# PIC32CM5164LE00048 register map
Vendor: Microchip Technology; Series: PIC32CMLE00; File version: 0
CPU: CM23 r0p0, little endian, MPU, no FPU, 2 interrupt priority bits, 71 interrupts
Registers are 32-bit, read-write, reset 0x0 unless marked. A register's access mark holds for its fields unless they carry their own. Offsets are from the block's base; [hi:lo] are bit positions; lines under a group give offsets from that group; {n}, {i} and the like mark numbered series; 'fields as' and 'values as' point back to an identical list.

## SERCOM0 — Serial Communication Interface
Base 0x42000400; register names take the prefix SERCOM_
Same registers: SERCOM1 0x42000800, SERCOM2 0x42000C00, SERCOM3 0x42001000, SERCOM4 0x42001400, SERCOM5 0x42001800
0x00 I2CM group — I2C Master Mode
  0x00 CTRLA — I2CM Control A
    [30] LOWTOUTEN — SCL Low Timeout Enable
    [29:28] INACTOUT — Inactive Time-Out
      0=DIS (Disable); 1=55US (5-6 SCL cycle time-out); 2=105US (10-11 SCL cycle time-out); 3=205US (20-21 SCL cycle time-out)
    [27] SCLSM — SCL Clock Stretch Mode
    [25:24] SPEED — Transfer Speed
      0=SM (Standard-Mode (SM) and Fast-Mode (FM)); 1=FMP (Fast-Mode Plus (FM+)); 2=HS (High-Speed Mode)
    [23] SEXTTOEN — Slave SCL Low Extend Timeout
    [22] MEXTTOEN — Master SCL Low Extend Timeout
    [21:20] SDAHOLD — SDA Hold Time
      0=DIS (Disabled); 1=75NS (50-100ns hold time); 2=450NS (300-600ns hold time); 3=600NS (400-800ns hold time)
    [16] PINOUT — Pin Usage
    [7] RUNSTDBY — Run in Standby
    [4:2] MODE — Operating Mode
      5=I2C_MASTER (I2C master operation)
    [1] ENABLE
    [0] SWRST — Software Reset
  0x04 CTRLB — I2CM Control B
    [23:22] FIFOCLR — FIFO Clear
      0=NONE (No action); 1=TXFIFO (Clear TX FIFO); 2=RXFIFO (Clear RX FIFO); 3=BOTH (Clear both TX and RF FIFOs)
    [18] ACKACT — Acknowledge Action
    [17:16] CMD — Command
    [9] QCEN — Quick Command Enable
    [8] SMEN — Smart Mode Enable
  0x08 CTRLC — I2CM Control C
    [31:30] TXTRHOLD — Transmit FIFO Threshold
      0=DEFAULT (Interrupt and DMA triggers are generated as long as the FIFO is not full); 1=HALF (Interrupt and DMA triggers are generated when half FIFO space is free); 2=EMPTY (Interrupt and DMA triggers are generated as long as the FIFO is not full)
    [29:28] RXTRHOLD — Receive FIFO Threshold
      0=DEFAULT (Interrupt and DMA triggers are generated when DATA is present in the FIFO); 1=HALF (Interrupt and DMA triggers are generated when FIFO is half-full); 2=FULL (Interrupt and DMA triggers are generated when FIFO is full)
    [27] FIFOEN — FIFO Enable
    [24] DATA32B — Data 32 Bit
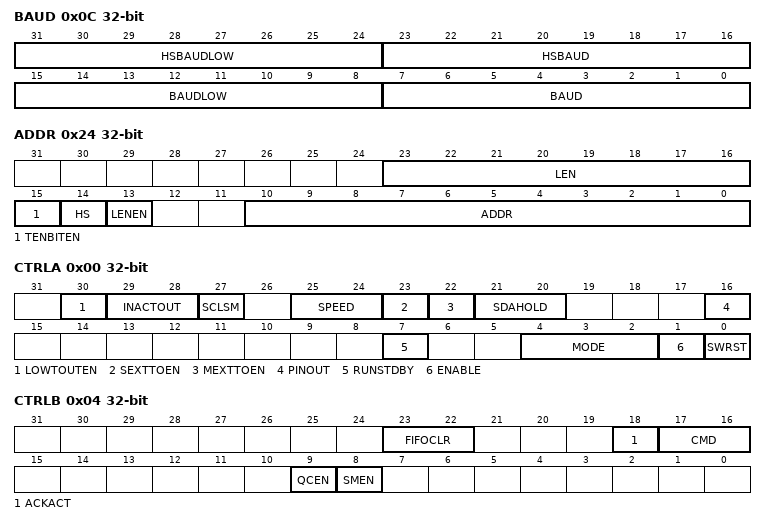
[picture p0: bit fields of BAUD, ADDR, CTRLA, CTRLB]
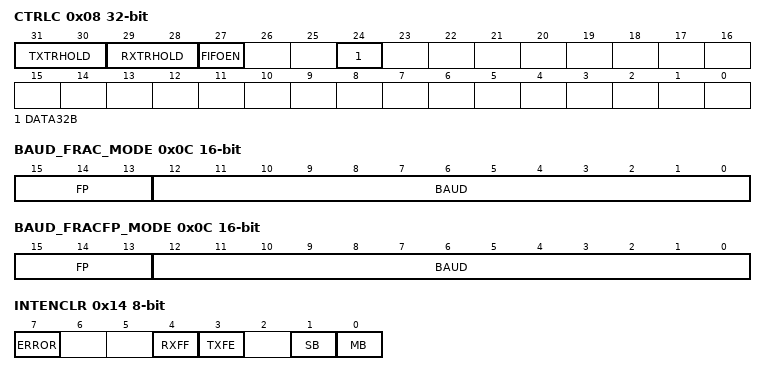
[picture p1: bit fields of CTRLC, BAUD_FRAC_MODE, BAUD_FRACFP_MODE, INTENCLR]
  0x0C BAUD — I2CM Baud Rate
    [31:24] HSBAUDLOW — High Speed Baud Rate Value Low
    [23:16] HSBAUD — High Speed Baud Rate Value
    [15:8] BAUDLOW — Baud Rate Value Low
    [7:0] BAUD — Baud Rate Value
  0x14 INTENCLR 8-bit write-1-clears — I2CM Interrupt Enable Clear
    [7] ERROR — Combined Error Interrupt Disable
    [4] RXFF — Rx FIFO Full Interrupt Disable
    [3] TXFE — Tx FIFO Empty Interrupt Disable
    [1] SB — Slave On Bus Interrupt Disable
    [0] MB — Master On Bus Interrupt Disable
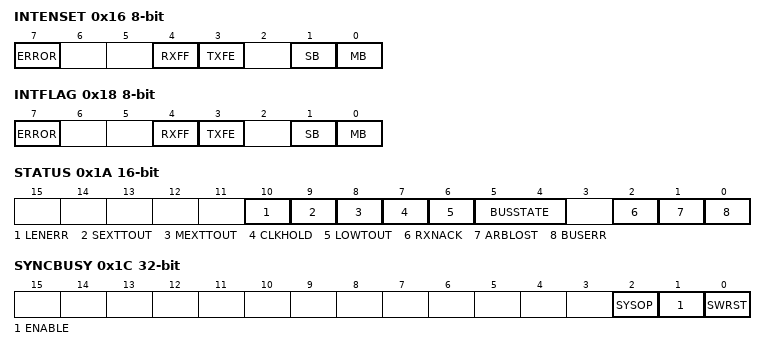
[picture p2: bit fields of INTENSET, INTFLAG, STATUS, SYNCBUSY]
  0x16 INTENSET 8-bit write-1-sets — I2CM Interrupt Enable Set
    [7] ERROR — Combined Error Interrupt Enable
    [4] RXFF — Rx FIFO Full Interrupt Enable
    [3] TXFE — Tx FIFO Empty Interrupt Enable
    [1] SB — Slave On Bus Interrupt Enable
    [0] MB — Master On Bus Interrupt Enable
  0x18 INTFLAG 8-bit write-1-clears — I2CM Interrupt Flag Status and Clear
    [7] ERROR — Combined Error Interrupt
    [4] RXFF — Rx FIFO Full Interrupt
    [3] TXFE — Tx FIFO Empty Interrupt
    [1] SB — Slave On Bus Interrupt
    [0] MB — Master On Bus Interrupt
  0x1A STATUS 16-bit — I2CM Status
    [10] LENERR — Length Error
    [9] SEXTTOUT — Slave SCL Low Extend Timeout
    [8] MEXTTOUT — Master SCL Low Extend Timeout
    [7] CLKHOLD — Clock Hold
    [6] LOWTOUT — SCL Low Timeout
    [5:4] BUSSTATE
      0=UNKNOWN (Wait for stop or idle); 1=IDLE (Wait for transaction initialization); 2=OWNER (I2C master is the current owner of the bus); 3=BUSY (Some other I2C master owns the bus)
    [2] RXNACK — Received Not Acknowledge
    [1] ARBLOST — Arbitration Lost
    [0] BUSERR — Bus Error
  0x1C SYNCBUSY ro — I2CM Synchronization Busy
    [2] SYSOP — System Operation Synchronization Busy
    [1] ENABLE — SERCOM Enable Synchronization Busy
    [0] SWRST — Software Reset Synchronization Busy
  0x24 ADDR — I2CM Address
    [23:16] LEN — Length
    [15] TENBITEN — Ten Bit Addressing Enable
    [14] HS — High Speed Mode
    [13] LENEN — Length Enable
    [10:0] ADDR — Address Value
  0x28 DATA — I2CM Data
    [31:0] DATA — Data Value
  0x30 DBGCTRL 8-bit — I2CM Debug Control
    [0] DBGSTOP — Debug Mode
  0x34 FIFOSPACE 16-bit ro — I2CM FIFO Space
    [12:8] RXSPACE — Rx FIFO Filled Space
    [4:0] TXSPACE — Tx FIFO Empty Space
  0x36 FIFOPTR 16-bit — I2CM FIFO CPU Pointers
    [11:8] CPURDPTR — CPU FIFO Read Pointer
    [3:0] CPUWRPTR — CPU FIFO Write Pointer
0x00 I2CS group (alternate view of I2CM) — I2C Slave Mode
  0x00 CTRLA — I2CS Control A
    [30] LOWTOUTEN — SCL Low Timeout Enable
    [27] SCLSM — SCL Clock Stretch Mode
    [25:24] SPEED — Transfer Speed
      values as I2CM.CTRLA.SPEED
    [23] SEXTTOEN — Slave SCL Low Extend Timeout
    [21:20] SDAHOLD — SDA Hold Time
      values as I2CM.CTRLA.SDAHOLD
    [16] PINOUT — Pin Usage
    [7] RUNSTDBY — Run during Standby
    [4:2] MODE — Operating Mode
      4=I2C_SLAVE (I2C slave operation)
    [1] ENABLE
    [0] SWRST — Software Reset
  0x04 CTRLB — I2CS Control B
    [23:22] FIFOCLR — FIFO Clear
      values as I2CM.CTRLB.FIFOCLR
    [18] ACKACT — Acknowledge Action
    [17:16] CMD — Command
    [15:14] AMODE — Address Mode
      0=MASK (The slave responds to the address written in ADDR.ADDR masked by the value in ADDR.ADDRMASK); 1=2ADDRS (The slave responds to the two unique addresses in ADDR and ADDRMASK); 2=RANGE (The slave responds to the range of addresses between and including ADDR and ADDRMASK. ADDR is the upper limit)
    [10] AACKEN — Automatic Address Acknowledge
    [9] GCMD — PMBus Group Command
    [8] SMEN — Smart Mode Enable
  0x08 CTRLC — I2CS Control C
    [31:30] TXTRHOLD — Transmit FIFO Threshold
      values as I2CM.CTRLC.TXTRHOLD
    [29:28] RXTRHOLD — Receive FIFO Threshold
      values as I2CM.CTRLC.RXTRHOLD
    [27] FIFOEN — FIFO Enable
    [24] DATA32B — Data 32 Bit
    [3:0] SDASETUP — SDA Setup Time
  0x14 INTENCLR 8-bit write-1-clears — I2CS Interrupt Enable Clear
    [7] ERROR — Combined Error Interrupt Disable
    [4] RXFF — Rx FIFO Full Interrupt Disable
    [3] TXFE — Tx FIFO Empty Interrupt Disable
    [2] DRDY — Data Interrupt Disable
    [1] AMATCH — Address Match Interrupt Disable
    [0] PREC — Stop Received Interrupt Disable
  0x16 INTENSET 8-bit write-1-sets — I2CS Interrupt Enable Set
    [7] ERROR — Combined Error Interrupt Enable
    [4] RXFF — Rx FIFO Full Interrupt Enable
    [3] TXFE — Tx FIFO Empty Interrupt Enable
    [2] DRDY — Data Interrupt Enable
    [1] AMATCH — Address Match Interrupt Enable
    [0] PREC — Stop Received Interrupt Enable
  0x18 INTFLAG 8-bit write-1-clears — I2CS Interrupt Flag Status and Clear
    [7] ERROR — Combined Error Interrupt
    [4] RXFF — Rx FIFO Full Interrupt
    [3] TXFE — Tx FIFO Empty Interrupt
    [2] DRDY — Data Interrupt
    [1] AMATCH — Address Match Interrupt
    [0] PREC — Stop Received Interrupt
  0x1A STATUS 16-bit — I2CS Status
    [11] LENERR — Transaction Length Error
    [10] HS — High Speed
    [9] SEXTTOUT — Slave SCL Low Extend Timeout
    [7] CLKHOLD — Clock Hold
    [6] LOWTOUT — SCL Low Timeout
    [4] SR — Repeated Start
    [3] DIR — Read/Write Direction
    [2] RXNACK — Received Not Acknowledge
    [1] COLL — Transmit Collision
    [0] BUSERR — Bus Error
  0x1C SYNCBUSY ro — I2CS Synchronization Busy
    [4] LENGTH — Length Synchronization Busy
    [2] SYSOP — System Operation Synchronization Busy
    [1] ENABLE — SERCOM Enable Synchronization Busy
    [0] SWRST — Software Reset Synchronization Busy
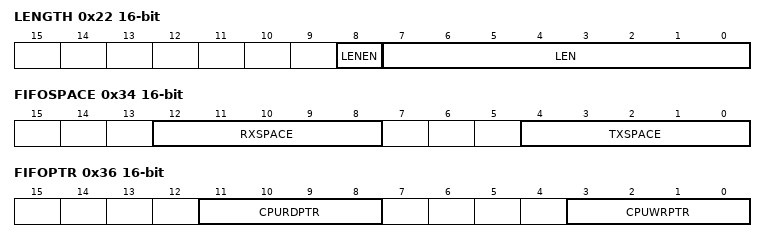
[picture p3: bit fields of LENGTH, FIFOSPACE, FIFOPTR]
  0x22 LENGTH 16-bit — I2CS Length
    [8] LENEN — Data Length Enable
    [7:0] LEN — Data Length
  0x24 ADDR — I2CS Address
    [26:17] ADDRMASK — Address Mask
    [15] TENBITEN — Ten Bit Addressing Enable
    [10:1] ADDR — Address Value
    [0] GENCEN — General Call Address Enable
  0x28 DATA — I2CS Data
    [31:0] DATA — Data Value
  0x34 FIFOSPACE 16-bit ro — I2CS FIFO Space
    fields as I2CM.FIFOSPACE
  0x36 FIFOPTR 16-bit — I2CS FIFO CPU Pointers
    fields as I2CM.FIFOPTR
0x00 SPIS group (alternate view of I2CM) — SPI Slave Mode
  0x00 CTRLA — SPIS Control A
    [30] DORD — Data Order
      0=MSB (MSB is transmitted first); 1=LSB (LSB is transmitted first)
    [29] CPOL — Clock Polarity
      0=IDLE_LOW (SCK is low when idle); 1=IDLE_HIGH (SCK is high when idle)
    [28] CPHA — Clock Phase
      0=LEADING_EDGE (The data is sampled on a leading SCK edge and changed on a trailing SCK edge); 1=TRAILING_EDGE (The data is sampled on a trailing SCK edge and changed on a leading SCK edge)
    [27:24] FORM — Frame Format
      0=SPI_FRAME; 2=SPI_FRAME_WITH_ADDR
    [21:20] DIPO — Data In Pinout
      {v}=PAD{v} (SERCOM PAD[{v}] is used as data input) (v=0..3)
    [17:16] DOPO — Data Out Pinout
      0=PAD0 (DO on PAD[0], SCK on PAD[1] and SS on PAD[2]); 2=PAD3 (DO on PAD[3], SCK on PAD[1] and SS on PAD[2])
    [8] IBON — Immediate Buffer Overflow Notification
      0=STATUS.BUFOVF is set when it occurs in the data stream; 1=STATUS.BUFOVF is set immediately upon buffer overflow
    [7] RUNSTDBY — Run during Standby
    [4:2] MODE — Operating Mode
      2=SPI_SLAVE (SPI in slave operation)
    [1] ENABLE
    [0] SWRST — Software Reset
  0x04 CTRLB — SPIS Control B
    [23:22] FIFOCLR — FIFO Clear
      values as I2CM.CTRLB.FIFOCLR
    [17] RXEN — Receiver Enable
    [15:14] AMODE — Address Mode
      0=MASK (ADDRMASK is used as a mask to the AADR register); 1=2ADDRS (The slave responds to the two unique addresses in ADDR and ADDRMASK); 2=RANGE (The slave responds to the range of addresses between and including ADDR and ADDRMASK. ADDR is the upper limit)
    [13] MSSEN — Master Slave Select Enable
      0=DISABLE (Hardware SS control is disabled); 1=ENABLE (Hardware SS control is enabled)
    [9] SSDE — Slave Select Low Detect Enable
      0=DISABLE (SS low detector is disabled); 1=ENABLE (SS low detector is enabled)
    [6] PLOADEN — Data Preload Enable
    [2:0] CHSIZE — Character Size
      0=8_BIT (8 bits); 1=9_BIT (9 bits)
  0x08 CTRLC — SPIS Control C
    [31:30] TXTRHOLD — Transmit FIFO Threshold
      0=DEFAULT (Interrupt and DMA triggers are generated as long as the FIFO is not full); 1=HALF (Interrupt and DMA triggers are generated when half FIFO space is free); 2=EMPTY (Interrupt and DMA triggers are generated as long as the FIFO is empty)
    [29:28] RXTRHOLD — Receive FIFO Threshold
      values as I2CM.CTRLC.RXTRHOLD
    [27] FIFOEN — FIFO Enable
    [24] DATA32B — Data 32 Bit
    [5:0] ICSPACE — Inter-Character Spacing
  0x0C BAUD 8-bit — SPIS Baud Rate
    [7:0] BAUD — Baud Rate Value
  0x14 INTENCLR 8-bit write-1-clears — SPIS Interrupt Enable Clear
    [7] ERROR — Combined Error Interrupt Disable
    [3] SSL — Slave Select Low Interrupt Disable
    [2] RXC — Receive Complete Interrupt Disable
    [1] TXC — Transmit Complete Interrupt Disable
    [0] DRE — Data Register Empty Interrupt Disable
  0x16 INTENSET 8-bit write-1-sets — SPIS Interrupt Enable Set
    [7] ERROR — Combined Error Interrupt Enable
    [3] SSL — Slave Select Low Interrupt Enable
    [2] RXC — Receive Complete Interrupt Enable
    [1] TXC — Transmit Complete Interrupt Enable
    [0] DRE — Data Register Empty Interrupt Enable
  0x18 INTFLAG 8-bit write-1-clears — SPIS Interrupt Flag Status and Clear
    [7] ERROR — Combined Error Interrupt
    [3] SSL — Slave Select Low Interrupt Flag
    [2] RXC — Receive Complete Interrupt
    [1] TXC — Transmit Complete Interrupt
    [0] DRE — Data Register Empty Interrupt
  0x1A STATUS 16-bit — SPIS Status
    [11] LENERR — Transaction Length Error
    [2] BUFOVF — Buffer Overflow
  0x1C SYNCBUSY ro — SPIS Synchronization Busy
    [4] LENGTH — LENGTH Synchronization Busy
    [2] CTRLB — CTRLB Synchronization Busy
    [1] ENABLE — SERCOM Enable Synchronization Busy
    [0] SWRST — Software Reset Synchronization Busy
  0x22 LENGTH 16-bit — SPIS Length
    [8] LENEN — Data Length Enable
    [7:0] LEN — Data Length
  0x24 ADDR — SPIS Address
    [23:16] ADDRMASK — Address Mask
    [7:0] ADDR — Address Value
  0x28 DATA — SPIS Data
    [31:0] DATA — Data Value
  0x30 DBGCTRL 8-bit — SPIS Debug Control
    [0] DBGSTOP — Debug Mode
  0x34 FIFOSPACE 16-bit ro — SPIS FIFO Space
    fields as I2CM.FIFOSPACE
  0x36 FIFOPTR 16-bit — SPIS FIFO CPU Pointers
    fields as I2CM.FIFOPTR
0x00 SPIM group (alternate view of I2CM) — SPI Master Mode
  0x00 CTRLA — SPIM Control A
    [30] DORD — Data Order
      values as SPIS.CTRLA.DORD
    [29] CPOL — Clock Polarity
      values as SPIS.CTRLA.CPOL
    [28] CPHA — Clock Phase
      values as SPIS.CTRLA.CPHA
    [27:24] FORM — Frame Format
      0=SPI_FRAME; 2=SPI_FRAME_WITH_ADDR
    [21:20] DIPO — Data In Pinout
      {v}=PAD{v} (SERCOM PAD[{v}] is used as data input) (v=0..3)
    [17:16] DOPO — Data Out Pinout
      values as SPIS.CTRLA.DOPO
    [8] IBON — Immediate Buffer Overflow Notification
      values as SPIS.CTRLA.IBON
    [7] RUNSTDBY — Run during Standby
    [4:2] MODE — Operating Mode
      3=SPI_MASTER (SPI in master operation)
    [1] ENABLE
    [0] SWRST — Software Reset
  0x04 CTRLB — SPIM Control B
    fields as SPIS.CTRLB
  0x08 CTRLC — SPIM Control C
    fields as SPIS.CTRLC
  0x0C BAUD 8-bit — SPIM Baud Rate
    [7:0] BAUD — Baud Rate Value
  0x14 INTENCLR 8-bit write-1-clears — SPIM Interrupt Enable Clear
    fields as SPIS.INTENCLR
  0x16 INTENSET 8-bit write-1-sets — SPIM Interrupt Enable Set
    fields as SPIS.INTENSET
  0x18 INTFLAG 8-bit write-1-clears — SPIM Interrupt Flag Status and Clear
    fields as SPIS.INTFLAG
  0x1A STATUS 16-bit — SPIM Status
    fields as SPIS.STATUS
  0x1C SYNCBUSY ro — SPIM Synchronization Busy
    fields as SPIS.SYNCBUSY
  0x22 LENGTH 16-bit — SPIM Length
    [8] LENEN — Data Length Enable
    [7:0] LEN — Data Length
  0x24 ADDR — SPIM Address
    [23:16] ADDRMASK — Address Mask
    [7:0] ADDR — Address Value
  0x28 DATA — SPIM Data
    [31:0] DATA — Data Value
  0x30 DBGCTRL 8-bit — SPIM Debug Control
    [0] DBGSTOP — Debug Mode
  0x34 FIFOSPACE 16-bit ro — SPIM FIFO Space
    fields as I2CM.FIFOSPACE
  0x36 FIFOPTR 16-bit — SPIM FIFO CPU Pointers
    fields as I2CM.FIFOPTR
0x00 USART_EXT group (alternate view of I2CM) — USART EXTERNAL CLOCK Mode
  0x00 CTRLA — USART_EXT Control A
    [30] DORD — Data Order
      0=MSB (MSB is transmitted first.); 1=LSB (LSB is transmitted first.)
    [29] CPOL — Clock Polarity
      0=IDLE_LOW (TxD Change:- Rising XCK edge, RxD Sample:- Falling XCK edge); 1=IDLE_HIGH (TxD Change:- Falling XCK edge, RxD Sample:- Rising XCK edge)
    [28] CMODE — Communication Mode
      0=ASYNC (Asynchronous communication.); 1=SYNC (Synchronous communication.)
    [27:24] FORM — Frame Format
      0=USART_FRAME_NO_PARITY; 1=USART_FRAME_WITH_PARITY; 2=USART_FRAME_LINBRKGEN (LIN Master Break and Sync generation); 4=USART_FRAME_AUTO_BAUD_NO_PARITY (Auto-baud (LIN Slave) - break detection and auto-baud); 5=USART_FRAME_AUTO_BAUD_WITH_PARITY (Auto-baud - break detection and auto-baud with parity); 7=USART_FRAME_ISO_7816 (ISO 7816)
    [23:22] SAMPA — Sample Adjustment
      0=ADJ0 (16x Over-sampling = 7-8-9; 8x Over-sampling = 3-4-5); 1=ADJ1 (16x Over-sampling = 9-10-11; 8x Over-sampling = 4-5-6); 2=ADJ2 (16x Over-sampling = 11-12-13; 8x Over-sampling = 5-6-7); 3=ADJ3 (16x Over-sampling = 13-14-15; 8x Over-sampling = 6-7-8)
    [21:20] RXPO — Receive Data Pinout
      {v}=PAD{v} (SERCOM PAD[{v}] is used for data reception) (v=0..3)
    [17:16] TXPO — Transmit Data Pinout
      0=PAD0 (PAD[0] = TxD; PAD[1] = XCK); 2=PAD2 (PAD[0] = TxD; PAD[2] = RTS; PAD[3] = CTS); 3=PAD3 (PAD[0] = TxD; PAD[1] = XCK; PAD[2] = TE)
    [15:13] SAMPR — Sample
      0=16X_ARITHMETIC (16x over-sampling using arithmetic baudrate generation); 1=16X_FRACTIONAL (16x over-sampling using fractional baudrate generation); 2=8X_ARITHMETIC (8x over-sampling using arithmetic baudrate generation); 3=8X_FRACTIONAL (8x over-sampling using fractional baudrate generation); 4=3X_ARITHMETIC (3x over-sampling using arithmetic baudrate generation)
    [10] RXINV — Receive Data Invert
      0=DISABLE (RxD is not inverted); 1=INV (RxD is inverted)
    [9] TXINV — Transmit Data Invert
      0=DISABLE (TxD is not inverted); 1=INV (TxD is inverted)
    [8] IBON — Immediate Buffer Overflow Notification
    [7] RUNSTDBY — Run during Standby
    [4:2] MODE — Operating Mode
      0=USART_EXT_CLK (USART with external clock); 1=USART_INT_CLK (USART with internal clock)
    [1] ENABLE
    [0] SWRST — Software Reset
  0x04 CTRLB — USART_EXT Control B
    [25:24] LINCMD — LIN Command
      0=NONE (Normal USART transmission); 1=SOFTWARE_CONTROL_TRANSMIT_CMD (Break field is transmitted when DATA is written); 2=AUTO_TRANSMIT_CMD (Break, sync and identifier are automatically transmitted when DATA is written with the identifier)
    [23:22] FIFOCLR — FIFO Clear
      values as I2CM.CTRLB.FIFOCLR
    [17] RXEN — Receiver Enable
    [16] TXEN — Transmitter Enable
    [13] PMODE — Parity Mode
      0=EVEN (Even Parity); 1=ODD (Odd Parity)
    [10] ENC — Encoding Format
      0=DISABLE (Data is not encoded); 1=IRDA (Data is IrDA encoded)
    [9] SFDE — Start of Frame Detection Enable
    [8] COLDEN — Collision Detection Enable
    [6] SBMODE — Stop Bit Mode
      0=1_BIT (One Stop Bit); 1=2_BIT (Two Stop Bits)
    [2:0] CHSIZE — Character Size
      0=8_BIT (8 Bits); 1=9_BIT (9 Bits); 5=5_BIT (5 Bits); 6=6_BIT (6 Bits); 7=7_BIT (7 Bits)
  0x08 CTRLC — USART_EXT Control C
    [31:30] TXTRHOLD — Transmit FIFO Threshold
      0=DEFAULT (Interrupt and DMA triggers are generated as long as the FIFO is not full); 1=HALF (Interrupt and DMA triggers are generated when half FIFO space is free); 2=EMPTY (Interrupt and DMA triggers are generated when the FIFO is empty)
    [29:28] RXTRHOLD — Receive FIFO Threshold
      values as I2CM.CTRLC.RXTRHOLD
    [27] FIFOEN — FIFO Enable
    [25:24] DATA32B — Data 32 Bit
      0=Reads and writes with CHSIZE; 1=Reads with CHSIZE, writes with 32-bit extension; 2=Reads with 32-bit extension, writes with CHSIZE; 3=Reads and writes with 32-bit extension
    [22:20] MAXITER — Maximum Iterations
    [17] DSNACK — Disable Successive NACK
    [16] INACK — Inhibit Not Acknowledge
    [11:10] HDRDLY — LIN Master Header Delay
      0=DELAY0 (Delay between break and sync transmission is 1 bit time; Delay between sync and ID transmission is 1 bit time); 1=DELAY1 (Delay between break and sync transmission is 4 bit time; Delay between sync and ID transmission is 4 bit time); 2=DELAY2 (Delay between break and sync transmission is 8 bit time; Delay between sync and ID transmission is 4 bit time); 3=DELAY3 (Delay between break and sync transmission is 14 bit time; Delay between sync and ID transmission is 4 bit time)
    [9:8] BRKLEN — LIN Master Break Length
      0=13_BIT (Break field transmission is 13 bit times); 1=17_BIT (Break field transmission is 17 bit times); 2=21_BIT (Break field transmission is 21 bit times); 3=26_BIT (Break field transmission is 26 bit times)
    [2:0] GTIME — Guard Time
  0x0C BAUD 16-bit — USART_EXT Baud Rate
    [15:0] BAUD — Baud Rate Value
  0x0C BAUD_FRAC_MODE 16-bit (alternate view of BAUD) — USART_EXT Baud Rate
    [15:13] FP — Fractional Part
    [12:0] BAUD — Baud Rate Value
  0x0C BAUD_FRACFP_MODE 16-bit (alternate view of BAUD) — USART_EXT Baud Rate
    [15:13] FP — Fractional Part
    [12:0] BAUD — Baud Rate Value
  0x0C BAUD_USARTFP_MODE 16-bit (alternate view of BAUD) — USART_EXT Baud Rate
    [15:0] BAUD — Baud Rate Value
  0x0E RXPL 8-bit — USART_EXT Receive Pulse Length
    [7:0] RXPL — Receive Pulse Length
  0x14 INTENCLR 8-bit write-1-clears — USART_EXT Interrupt Enable Clear
    [7] ERROR — Combined Error Interrupt Disable
    [5] RXBRK — Break Received Interrupt Disable
    [4] CTSIC — Clear To Send Input Change Interrupt Disable
    [3] RXS — Receive Start Interrupt Disable
    [2] RXC — Receive Complete Interrupt Disable
    [1] TXC — Transmit Complete Interrupt Disable
    [0] DRE — Data Register Empty Interrupt Disable
  0x16 INTENSET 8-bit write-1-sets — USART_EXT Interrupt Enable Set
    [7] ERROR — Combined Error Interrupt Enable
    [5] RXBRK — Break Received Interrupt Enable
    [4] CTSIC — Clear To Send Input Change Interrupt Enable
    [3] RXS — Receive Start Interrupt Enable
    [2] RXC — Receive Complete Interrupt Enable
    [1] TXC — Transmit Complete Interrupt Enable
    [0] DRE — Data Register Empty Interrupt Enable
  0x18 INTFLAG 8-bit write-1-clears — USART_EXT Interrupt Flag Status and Clear
    [7] ERROR — Combined Error Interrupt
    [5] RXBRK — Break Received Interrupt
    [4] CTSIC — Clear To Send Input Change Interrupt
    [3] RXS — Receive Start Interrupt
    [2] RXC — Receive Complete Interrupt
    [1] TXC — Transmit Complete Interrupt
    [0] DRE — Data Register Empty Interrupt
  0x1A STATUS 16-bit — USART_EXT Status
    [7] ITER — Maximum Number of Repetitions Reached
    [6] TXE — Transmitter Empty
    [5] COLL — Collision Detected
    [4] ISF — Inconsistent Sync Field
    [3] CTS — Clear To Send
    [2] BUFOVF — Buffer Overflow
    [1] FERR — Frame Error
    [0] PERR — Parity Error
  0x1C SYNCBUSY ro — USART_EXT Synchronization Busy
    [4] LENGTH — LENGTH Synchronization Busy
    [3] RXERRCNT — RXERRCNT Synchronization Busy
    [2] CTRLB — CTRLB Synchronization Busy
    [1] ENABLE — SERCOM Enable Synchronization Busy
    [0] SWRST — Software Reset Synchronization Busy
  0x20 RXERRCNT 8-bit ro — USART_EXT Receive Error Count
    [7:0] RXERRCNT — Receive Error Count
  0x22 LENGTH 16-bit — USART_EXT Length
    [9:8] LENEN — Data Length Enable
      0=DISABLE (Length counter is disabled); 1=TX (Length counter is enabled for transmit); 2=RX (Length counter is enabled for receive)
    [7:0] LEN — Data Length
  0x28 DATA — USART_EXT Data
    [31:0] DATA — Data Value
  0x30 DBGCTRL 8-bit — USART_EXT Debug Control
    [0] DBGSTOP — Debug Mode
  0x34 FIFOSPACE 16-bit ro — USART_EXT FIFO Space
    fields as I2CM.FIFOSPACE
  0x36 FIFOPTR 16-bit — USART_EXT FIFO CPU Pointers
    fields as I2CM.FIFOPTR
0x00 USART_INT group (alternate view of I2CM) — USART INTERNAL CLOCK Mode
  0x00 CTRLA — USART_INT Control A
    fields as USART_EXT.CTRLA
  0x04 CTRLB — USART_INT Control B
    fields as USART_EXT.CTRLB
  0x08 CTRLC — USART_INT Control C
    fields as USART_EXT.CTRLC
  0x0C BAUD 16-bit — USART_INT Baud Rate
    [15:0] BAUD — Baud Rate Value
  0x0C BAUD_FRAC_MODE 16-bit (alternate view of BAUD) — USART_INT Baud Rate
    [15:13] FP — Fractional Part
    [12:0] BAUD — Baud Rate Value
  0x0C BAUD_FRACFP_MODE 16-bit (alternate view of BAUD) — USART_INT Baud Rate
    [15:13] FP — Fractional Part
    [12:0] BAUD — Baud Rate Value
  0x0C BAUD_USARTFP_MODE 16-bit (alternate view of BAUD) — USART_INT Baud Rate
    [15:0] BAUD — Baud Rate Value
  0x0E RXPL 8-bit — USART_INT Receive Pulse Length
    [7:0] RXPL — Receive Pulse Length
  0x14 INTENCLR 8-bit write-1-clears — USART_INT Interrupt Enable Clear
    fields as USART_EXT.INTENCLR
  0x16 INTENSET 8-bit write-1-sets — USART_INT Interrupt Enable Set
    fields as USART_EXT.INTENSET
  0x18 INTFLAG 8-bit write-1-clears — USART_INT Interrupt Flag Status and Clear
    fields as USART_EXT.INTFLAG
  0x1A STATUS 16-bit — USART_INT Status
    fields as USART_EXT.STATUS
  0x1C SYNCBUSY ro — USART_INT Synchronization Busy
    fields as USART_EXT.SYNCBUSY
  0x20 RXERRCNT 8-bit ro — USART_INT Receive Error Count
    [7:0] RXERRCNT — Receive Error Count
  0x22 LENGTH 16-bit — USART_INT Length
    fields as USART_EXT.LENGTH
  0x28 DATA — USART_INT Data
    [31:0] DATA — Data Value
  0x30 DBGCTRL 8-bit — USART_INT Debug Control
    [0] DBGSTOP — Debug Mode
  0x34 FIFOSPACE 16-bit ro — USART_INT FIFO Space
    fields as I2CM.FIFOSPACE
  0x36 FIFOPTR 16-bit — USART_INT FIFO CPU Pointers
    fields as I2CM.FIFOPTR

## Notices in the file
Copyright (c) 2026 Microchip Technology Inc.
SPDX-License-Identifier: Apache-2.0
Licensed under the Apache License, Version 2.0 (the "License");
you may not use this file except in compliance with the License.
You may obtain a copy of the License at
http://www.apache.org/licenses/LICENSE-2.0
Unless required by applicable law or agreed to in writing, software
distributed under the License is distributed on an "AS IS" BASIS,
WITHOUT WARRANTIES OR CONDITIONS OF ANY KIND, either express or implied.
See the License for the specific language governing permissions and
limitations under the License.
